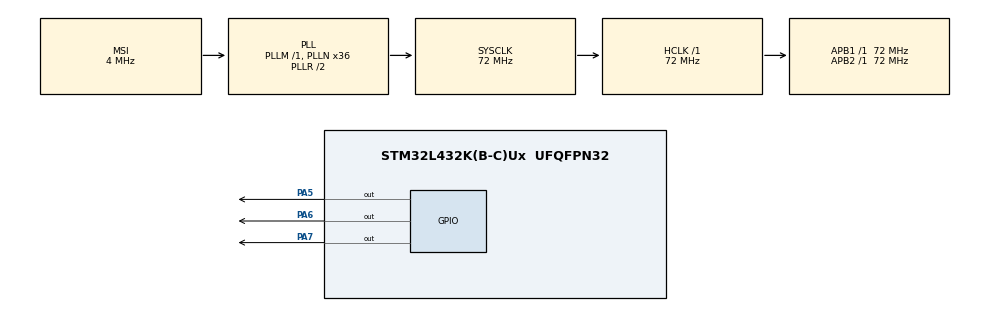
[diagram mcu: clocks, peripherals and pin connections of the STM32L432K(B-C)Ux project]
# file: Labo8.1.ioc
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Mcu.Family=STM32L4
Mcu.Name=STM32L432K(B-C)Ux
Mcu.Package=UFQFPN32
NVIC.PriorityGroup=NVIC_PRIORITYGROUP_4
PA13\ (JTMS-SWDIO).Mode=Serial_Wire
PA13\ (JTMS-SWDIO).Signal=SYS_JTMS-SWDIO
PA14\ (JTCK-SWCLK).Mode=Serial_Wire
PA14\ (JTCK-SWCLK).Signal=SYS_JTCK-SWCLK
PA5.Signal=GPIO_Output
PA6.Signal=GPIO_Output
PA7.Signal=GPIO_Output
PC14-OSC32_IN\ (PC14).Mode=LSE-External-Oscillator
PC14-OSC32_IN\ (PC14).Signal=RCC_OSC32_IN
PC15-OSC32_OUT\ (PC15).Mode=LSE-External-Oscillator
PC15-OSC32_OUT\ (PC15).Signal=RCC_OSC32_OUT
ProjectManager.HeapSize=0x200
ProjectManager.StackSize=0x400
ProjectManager.TargetToolchain=STM32CubeIDE
RCC.AHBFreq_Value=72000000
RCC.APB1Freq_Value=72000000
RCC.APB1TimFreq_Value=72000000
RCC.APB2Freq_Value=72000000
RCC.APB2TimFreq_Value=72000000
RCC.CortexFreq_Value=72000000
RCC.HCLKFreq_Value=72000000
RCC.HSE_VALUE=8000000
RCC.HSI48_VALUE=48000000
RCC.HSI_VALUE=16000000
RCC.MSI_VALUE=4000000
RCC.PLLN=36
RCC.SYSCLKFreq_VALUE=72000000
RCC.SYSCLKSource=RCC_SYSCLKSOURCE_PLLCLK
RCC.VCOOutputFreq_Value=144000000
board=custom

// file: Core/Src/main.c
/* USER CODE BEGIN Header */
/**
  ******************************************************************************
  * @file           : main.c
  * @brief          : Main program body
  ******************************************************************************
  * @attention
  *
  * Copyright (c) 2022 STMicroelectronics.
  * All rights reserved.
  *
  * This software is licensed under terms that can be found in the LICENSE file
  * in the root directory of this software component.
  * If no LICENSE file comes with this software, it is provided AS-IS.
  *
  ******************************************************************************
  */
/* USER CODE END Header */
#include "main.h"

void SystemClock_Config(void);
static void MX_GPIO_Init(void);

/* USER CODE BEGIN 0 */
uint8_t display[38][8]={
	{0x44,0x44,0x44,0x7C,0x44,0x44,0x44,0x44},// H
	{0x3C,0x42,0x42,0x42,0x42,0x42,0x42,0x3C},// O
	{0x40,0x40,0x40,0x40,0x40,0x40,0x40,0x7C},// L
	{0x18,0x24,0x42,0x42,0x7E1,0x42,0x42,0x42}// A
};
void write_byte (uint8_t byte){
	for (int i =0; i<8; i++){
		HAL_GPIO_WritePin (GPIOA, GPIO_PIN_5, 0);
		HAL_GPIO_WritePin (GPIOA, GPIO_PIN_7, byte&0x80);
		byte = byte <<1;
		HAL_GPIO_WritePin(GPIOA, GPIO_PIN_5, 1);
	}
}
void write_max(uint8_t address, uint8_t data){
	HAL_GPIO_WritePin (GPIOA, GPIO_PIN_6,0);
	write_byte (address);
	write_byte (data);
	HAL_GPIO_WritePin (GPIOA, GPIO_PIN_6,1);
}

void max_init(void){
	write_max(0x09, 0x00);
	write_max(0x0a, 0x00);
	write_max(0x0b, 0x00);
	write_max(0x0c, 0x00);
	write_max(0x0f, 0x00);
}

void write_string (char *str){
	while (*str){
		for (int i=1;i<9;i++){
			write_max (i, display[(*str - 55)][i-1]);
		}
		*str++;
		HAL_Delay (500);
	}
}
/* USER CODE END 0 */

int main(void)
{

  /* MCU Configuration--------------------------------------------------------*/

  /* Reset of all peripherals, Initializes the Flash interface and the Systick. */
  HAL_Init();

  /* USER CODE BEGIN Init */
  max_init ();
  /* USER CODE END Init */

  /* Configure the system clock */
  SystemClock_Config();

  /* Initialize all configured peripherals */
  MX_GPIO_Init();

  /* Infinite loop */
  while (1)
  {

    /* USER CODE BEGIN 3 */
	for (int j=0; j<38; j++){
		for (int i = 1; i<9;i++){
			write_max (i, display[j][i-1]);
		}
		HAL_Delay (700);
	}

  }
  /* USER CODE END 3 */
}

void SystemClock_Config(void)
{
  RCC_OscInitTypeDef RCC_OscInitStruct = {0};
  RCC_ClkInitTypeDef RCC_ClkInitStruct = {0};

  /** Configure the main internal regulator output voltage
  */
  if (HAL_PWREx_ControlVoltageScaling(PWR_REGULATOR_VOLTAGE_SCALE1) != HAL_OK)
  {
    Error_Handler();
  }

  /** Configure LSE Drive Capability
  */
  HAL_PWR_EnableBkUpAccess();
  __HAL_RCC_LSEDRIVE_CONFIG(RCC_LSEDRIVE_LOW);

  /** Initializes the RCC Oscillators according to the specified parameters
  * in the RCC_OscInitTypeDef structure.
  */
  RCC_OscInitStruct.OscillatorType = RCC_OSCILLATORTYPE_LSE|RCC_OSCILLATORTYPE_MSI;
  RCC_OscInitStruct.LSEState = RCC_LSE_ON;
  RCC_OscInitStruct.MSIState = RCC_MSI_ON;
  RCC_OscInitStruct.MSICalibrationValue = 0;
  RCC_OscInitStruct.MSIClockRange = RCC_MSIRANGE_6;
  RCC_OscInitStruct.PLL.PLLState = RCC_PLL_ON;
  RCC_OscInitStruct.PLL.PLLSource = RCC_PLLSOURCE_MSI;
  RCC_OscInitStruct.PLL.PLLM = 1;
  RCC_OscInitStruct.PLL.PLLN = 36;
  RCC_OscInitStruct.PLL.PLLP = RCC_PLLP_DIV7;
  RCC_OscInitStruct.PLL.PLLQ = RCC_PLLQ_DIV2;
  RCC_OscInitStruct.PLL.PLLR = RCC_PLLR_DIV2;
  if (HAL_RCC_OscConfig(&RCC_OscInitStruct) != HAL_OK)
  {
    Error_Handler();
  }

  /** Initializes the CPU, AHB and APB buses clocks
  */
  RCC_ClkInitStruct.ClockType = RCC_CLOCKTYPE_HCLK|RCC_CLOCKTYPE_SYSCLK
                              |RCC_CLOCKTYPE_PCLK1|RCC_CLOCKTYPE_PCLK2;
  RCC_ClkInitStruct.SYSCLKSource = RCC_SYSCLKSOURCE_PLLCLK;
  RCC_ClkInitStruct.AHBCLKDivider = RCC_SYSCLK_DIV1;
  RCC_ClkInitStruct.APB1CLKDivider = RCC_HCLK_DIV1;
  RCC_ClkInitStruct.APB2CLKDivider = RCC_HCLK_DIV1;

  if (HAL_RCC_ClockConfig(&RCC_ClkInitStruct, FLASH_LATENCY_4) != HAL_OK)
  {
    Error_Handler();
  }

  /** Enable MSI Auto calibration
  */
  HAL_RCCEx_EnableMSIPLLMode();
}

static void MX_GPIO_Init(void)
{
  GPIO_InitTypeDef GPIO_InitStruct = {0};

  /* GPIO Ports Clock Enable */
  __HAL_RCC_GPIOC_CLK_ENABLE();
  __HAL_RCC_GPIOA_CLK_ENABLE();

  /*Configure GPIO pin Output Level */
  HAL_GPIO_WritePin(GPIOA, GPIO_PIN_5|GPIO_PIN_6|GPIO_PIN_7, GPIO_PIN_RESET);

  /*Configure GPIO pins : PA5 PA6 PA7 */
  GPIO_InitStruct.Pin = GPIO_PIN_5|GPIO_PIN_6|GPIO_PIN_7;
  GPIO_InitStruct.Mode = GPIO_MODE_OUTPUT_PP;
  GPIO_InitStruct.Pull = GPIO_NOPULL;
  GPIO_InitStruct.Speed = GPIO_SPEED_FREQ_LOW;
  HAL_GPIO_Init(GPIOA, &GPIO_InitStruct);

}

void Error_Handler(void)
{
  __disable_irq();
  while (1)
  {
  }
}
